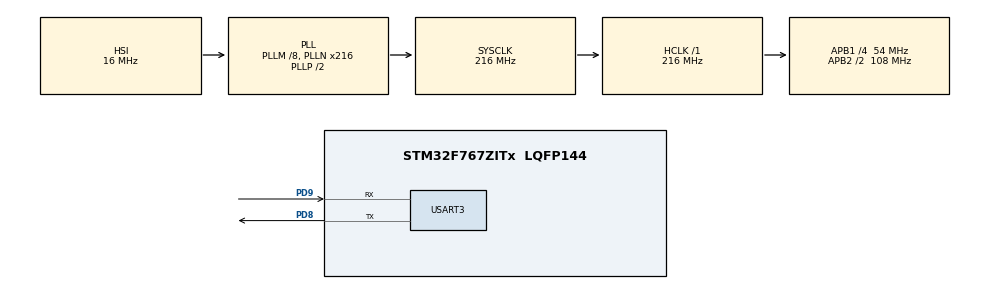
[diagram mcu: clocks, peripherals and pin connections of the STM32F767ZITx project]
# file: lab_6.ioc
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Mcu.Family=STM32F7
Mcu.Name=STM32F767ZITx
Mcu.Package=LQFP144
NVIC.PriorityGroup=NVIC_PRIORITYGROUP_2
NVIC.TIM1_UP_TIM10_IRQn=true\:1\:0\:true\:false\:true\:true\:true
NVIC.TIM2_IRQn=true\:2\:0\:true\:false\:true\:true\:true
PD8.Mode=Asynchronous
PD8.Signal=USART3_TX
PD9.Mode=Asynchronous
PD9.Signal=USART3_RX
ProjectManager.HeapSize=0x200
ProjectManager.StackSize=0x400
ProjectManager.TargetToolchain=STM32CubeIDE
RCC.AHBFreq_Value=216000000
RCC.APB1CLKDivider=RCC_HCLK_DIV4
RCC.APB1Freq_Value=54000000
RCC.APB1TimFreq_Value=108000000
RCC.APB2CLKDivider=RCC_HCLK_DIV2
RCC.APB2Freq_Value=108000000
RCC.APB2TimFreq_Value=216000000
RCC.CortexFreq_Value=216000000
RCC.HCLKFreq_Value=216000000
RCC.HSE_VALUE=25000000
RCC.HSI_VALUE=16000000
RCC.LSE_VALUE=32768
RCC.PLLM=8
RCC.PLLN=216
RCC.SYSCLKFreq_VALUE=216000000
RCC.SYSCLKSource=RCC_SYSCLKSOURCE_PLLCLK
RCC.USBFreq_Value=216000000
RCC.VCOOutputFreq_Value=432000000
TIM1.Period=1000-1
TIM1.Prescaler=216-1
TIM2.Period=400-1
TIM2.Prescaler=216-1
USART3.VirtualMode-Asynchronous=VM_ASYNC
VP_TIM1_VS_ClockSourceINT.Mode=Internal
VP_TIM2_VS_ClockSourceINT.Mode=Internal
board=custom

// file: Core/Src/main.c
/* USER CODE BEGIN Header */
/**
  ******************************************************************************
  * @file           : main.c
  * @brief          : Main program body
  ******************************************************************************
  * @attention
  *
  * <h2><center>&copy; Copyright (c) 2020 STMicroelectronics.
  * All rights reserved.</center></h2>
  *
  * This software component is licensed by ST under BSD 3-Clause license,
  * the "License"; You may not use this file except in compliance with the
  * License. You may obtain a copy of the License at:
  *                        opensource.org/licenses/BSD-3-Clause
  *
  ******************************************************************************
  */
/* USER CODE END Header */
#include "main.h"

/* USER CODE BEGIN Includes */
#include "stdio.h"
/* USER CODE END Includes */

TIM_HandleTypeDef htim1;
TIM_HandleTypeDef htim2;

UART_HandleTypeDef huart3;

/* USER CODE BEGIN PV */
uint32_t count;
uint8_t isDisplay;
uint32_t min=0;
uint32_t sec=0;
/* USER CODE END PV */

void SystemClock_Config(void);
static void MX_GPIO_Init(void);
static void MX_TIM1_Init(void);
static void MX_TIM2_Init(void);
static void MX_USART3_UART_Init(void);

int main(void)
{

  /* MCU Configuration--------------------------------------------------------*/

  /* Reset of all peripherals, Initializes the Flash interface and the Systick. */
  HAL_Init();

  /* Configure the system clock */
  SystemClock_Config();

  /* Initialize all configured peripherals */
  MX_GPIO_Init();
  MX_TIM1_Init();
  MX_TIM2_Init();
  MX_USART3_UART_Init();
  /* USER CODE BEGIN 2 */
  HAL_TIM_Base_Start_IT(&htim1);
  int n=2;
  char time_str[20];
  /* USER CODE END 2 */

  /* Infinite loop */
  /* USER CODE BEGIN WHILE */
  while (1)
  {
	  if(n==1){
		  displayNumber(count);
		  HAL_Delay(400);
	  }
	  else if(n==2){

		  //temporal increment
		  if(count>1000){
			  sec++;
			  count = 0;
		  }

		  //time control
		  if(sec == 60){
			  min++;
			  sec=0;
		  }

		  if(min==60){
			  min=0;
		  }

		  //render clock
		  sprintf(time_str,"  %02d:%02d\r",min,sec);
		  send_str(time_str);

	  }
    /* USER CODE END WHILE */

  }
}

void SystemClock_Config(void)
{
  RCC_OscInitTypeDef RCC_OscInitStruct = {0};
  RCC_ClkInitTypeDef RCC_ClkInitStruct = {0};
  RCC_PeriphCLKInitTypeDef PeriphClkInitStruct = {0};

  /** Configure the main internal regulator output voltage
  */
  __HAL_RCC_PWR_CLK_ENABLE();
  __HAL_PWR_VOLTAGESCALING_CONFIG(PWR_REGULATOR_VOLTAGE_SCALE1);
  /** Initializes the RCC Oscillators according to the specified parameters
  * in the RCC_OscInitTypeDef structure.
  */
  RCC_OscInitStruct.OscillatorType = RCC_OSCILLATORTYPE_HSI;
  RCC_OscInitStruct.HSIState = RCC_HSI_ON;
  RCC_OscInitStruct.HSICalibrationValue = RCC_HSICALIBRATION_DEFAULT;
  RCC_OscInitStruct.PLL.PLLState = RCC_PLL_ON;
  RCC_OscInitStruct.PLL.PLLSource = RCC_PLLSOURCE_HSI;
  RCC_OscInitStruct.PLL.PLLM = 8;
  RCC_OscInitStruct.PLL.PLLN = 216;
  RCC_OscInitStruct.PLL.PLLP = RCC_PLLP_DIV2;
  RCC_OscInitStruct.PLL.PLLQ = 2;
  if (HAL_RCC_OscConfig(&RCC_OscInitStruct) != HAL_OK)
  {
    Error_Handler();
  }
  /** Activate the Over-Drive mode
  */
  if (HAL_PWREx_EnableOverDrive() != HAL_OK)
  {
    Error_Handler();
  }
  /** Initializes the CPU, AHB and APB buses clocks
  */
  RCC_ClkInitStruct.ClockType = RCC_CLOCKTYPE_HCLK|RCC_CLOCKTYPE_SYSCLK
                              |RCC_CLOCKTYPE_PCLK1|RCC_CLOCKTYPE_PCLK2;
  RCC_ClkInitStruct.SYSCLKSource = RCC_SYSCLKSOURCE_PLLCLK;
  RCC_ClkInitStruct.AHBCLKDivider = RCC_SYSCLK_DIV1;
  RCC_ClkInitStruct.APB1CLKDivider = RCC_HCLK_DIV4;
  RCC_ClkInitStruct.APB2CLKDivider = RCC_HCLK_DIV2;

  if (HAL_RCC_ClockConfig(&RCC_ClkInitStruct, FLASH_LATENCY_7) != HAL_OK)
  {
    Error_Handler();
  }
  PeriphClkInitStruct.PeriphClockSelection = RCC_PERIPHCLK_USART3;
  PeriphClkInitStruct.Usart3ClockSelection = RCC_USART3CLKSOURCE_PCLK1;
  if (HAL_RCCEx_PeriphCLKConfig(&PeriphClkInitStruct) != HAL_OK)
  {
    Error_Handler();
  }
}

static void MX_TIM1_Init(void)
{

  TIM_ClockConfigTypeDef sClockSourceConfig = {0};
  TIM_MasterConfigTypeDef sMasterConfig = {0};

  htim1.Instance = TIM1;
  htim1.Init.Prescaler = 216-1;
  htim1.Init.CounterMode = TIM_COUNTERMODE_UP;
  htim1.Init.Period = 1000-1;
  htim1.Init.ClockDivision = TIM_CLOCKDIVISION_DIV1;
  htim1.Init.RepetitionCounter = 0;
  htim1.Init.AutoReloadPreload = TIM_AUTORELOAD_PRELOAD_DISABLE;
  if (HAL_TIM_Base_Init(&htim1) != HAL_OK)
  {
    Error_Handler();
  }
  sClockSourceConfig.ClockSource = TIM_CLOCKSOURCE_INTERNAL;
  if (HAL_TIM_ConfigClockSource(&htim1, &sClockSourceConfig) != HAL_OK)
  {
    Error_Handler();
  }
  sMasterConfig.MasterOutputTrigger = TIM_TRGO_RESET;
  sMasterConfig.MasterOutputTrigger2 = TIM_TRGO2_RESET;
  sMasterConfig.MasterSlaveMode = TIM_MASTERSLAVEMODE_DISABLE;
  if (HAL_TIMEx_MasterConfigSynchronization(&htim1, &sMasterConfig) != HAL_OK)
  {
    Error_Handler();
  }

}

static void MX_TIM2_Init(void)
{

  TIM_ClockConfigTypeDef sClockSourceConfig = {0};
  TIM_MasterConfigTypeDef sMasterConfig = {0};

  htim2.Instance = TIM2;
  htim2.Init.Prescaler = 216-1;
  htim2.Init.CounterMode = TIM_COUNTERMODE_UP;
  htim2.Init.Period = 400-1;
  htim2.Init.ClockDivision = TIM_CLOCKDIVISION_DIV1;
  htim2.Init.AutoReloadPreload = TIM_AUTORELOAD_PRELOAD_DISABLE;
  if (HAL_TIM_Base_Init(&htim2) != HAL_OK)
  {
    Error_Handler();
  }
  sClockSourceConfig.ClockSource = TIM_CLOCKSOURCE_INTERNAL;
  if (HAL_TIM_ConfigClockSource(&htim2, &sClockSourceConfig) != HAL_OK)
  {
    Error_Handler();
  }
  sMasterConfig.MasterOutputTrigger = TIM_TRGO_RESET;
  sMasterConfig.MasterSlaveMode = TIM_MASTERSLAVEMODE_DISABLE;
  if (HAL_TIMEx_MasterConfigSynchronization(&htim2, &sMasterConfig) != HAL_OK)
  {
    Error_Handler();
  }

}

static void MX_USART3_UART_Init(void)
{

  huart3.Instance = USART3;
  huart3.Init.BaudRate = 115200;
  huart3.Init.WordLength = UART_WORDLENGTH_8B;
  huart3.Init.StopBits = UART_STOPBITS_1;
  huart3.Init.Parity = UART_PARITY_NONE;
  huart3.Init.Mode = UART_MODE_TX_RX;
  huart3.Init.HwFlowCtl = UART_HWCONTROL_NONE;
  huart3.Init.OverSampling = UART_OVERSAMPLING_16;
  huart3.Init.OneBitSampling = UART_ONE_BIT_SAMPLE_DISABLE;
  huart3.AdvancedInit.AdvFeatureInit = UART_ADVFEATURE_NO_INIT;
  if (HAL_UART_Init(&huart3) != HAL_OK)
  {
    Error_Handler();
  }

}

static void MX_GPIO_Init(void)
{

  /* GPIO Ports Clock Enable */
  __HAL_RCC_GPIOD_CLK_ENABLE();

}

/* USER CODE BEGIN 4 */
void send_str(char* str) {
	while (__HAL_UART_GET_FLAG(&huart3,UART_FLAG_TC)==RESET);
	HAL_UART_Transmit(&huart3,(uint8_t*) str, strlen(str), 1000);
	HAL_Delay(100);
}

void displayNumber(uint32_t num){
	char str[20];
	sprintf(str, "%d\r\n", num);
	send_str(str);
}
/* USER CODE END 4 */

void Error_Handler(void)
{
}

/************************ (C) COPYRIGHT STMicroelectronics *****END OF FILE****/
